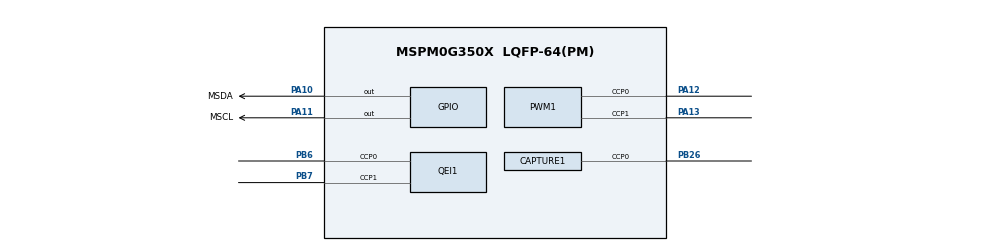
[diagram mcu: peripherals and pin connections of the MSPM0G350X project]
/**
 *
 * @cliArgs --device "MSPM0G350X" --part "Default" --package "LQFP-64(PM)" --product "mspm0_sdk@2.10.00.04"
 * @versions {"tool":"1.28.0+4696"}
 */

/**
 * Import the modules used in this configuration.
 */
const CAPTURE  = scripting.addModule("/ti/driverlib/CAPTURE", {}, false);
const CAPTURE1 = CAPTURE.addInstance();
const GPIO     = scripting.addModule("/ti/driverlib/GPIO", {}, false);
const GPIO1    = GPIO.addInstance();
const GPIO2    = GPIO.addInstance();
const GPIO3    = GPIO.addInstance();
const GPIO4    = GPIO.addInstance();
const GPIO5    = GPIO.addInstance();
const GPIO6    = GPIO.addInstance();
const PWM      = scripting.addModule("/ti/driverlib/PWM", {}, false);
const PWM1     = PWM.addInstance();
const QEI      = scripting.addModule("/ti/driverlib/QEI", {}, false);
const QEI1     = QEI.addInstance();
const SYSCTL   = scripting.addModule("/ti/driverlib/SYSCTL");
const TIMER    = scripting.addModule("/ti/driverlib/TIMER", {}, false);
const TIMER1   = TIMER.addInstance();

/**
 * Write custom configuration values to the imported modules.
 */
CAPTURE1.$name                          = "CAPTURE_0";
CAPTURE1.interrupts                     = ["CC0_UP"];
CAPTURE1.multi_countMode                = "DL_TIMER_COUNT_MODE_UP";
CAPTURE1.captureInputMode               = "multi";
CAPTURE1.multi_countRep                 = "DL_TIMER_REPEAT_MODE_ENABLED";
CAPTURE1.ccIndexMulti                   = [0];
CAPTURE1.peripheral.$assign             = "TIMG6";
CAPTURE1.peripheral.ccp0Pin.$assign     = "PB26";
CAPTURE1.ccp0PinConfig.$name            = "ti_driverlib_gpio_GPIOPinGeneric4";
CAPTURE1.ccp0PinConfig.enableConfig     = true;
CAPTURE1.ccp0PinConfig.internalResistor = "PULL_UP";

const Board = scripting.addModule("/ti/driverlib/Board", {}, false);

GPIO1.$name                              = "GPIO_GRP_0";
GPIO1.port                               = "PORTB";
GPIO1.associatedPins.create(8);
GPIO1.associatedPins[0].$name            = "PIN_9";
GPIO1.associatedPins[0].direction        = "INPUT";
GPIO1.associatedPins[0].assignedPin      = "9";
GPIO1.associatedPins[0].internalResistor = "PULL_UP";
GPIO1.associatedPins[1].$name            = "PIN_10";
GPIO1.associatedPins[1].direction        = "INPUT";
GPIO1.associatedPins[1].internalResistor = "PULL_UP";
GPIO1.associatedPins[1].assignedPin      = "10";
GPIO1.associatedPins[2].$name            = "PIN_11";
GPIO1.associatedPins[2].assignedPin      = "11";
GPIO1.associatedPins[2].direction        = "INPUT";
GPIO1.associatedPins[2].internalResistor = "PULL_UP";
GPIO1.associatedPins[3].$name            = "PIN_12";
GPIO1.associatedPins[3].direction        = "INPUT";
GPIO1.associatedPins[3].internalResistor = "PULL_UP";
GPIO1.associatedPins[3].assignedPin      = "12";
GPIO1.associatedPins[4].$name            = "PIN_13";
GPIO1.associatedPins[4].assignedPin      = "13";
GPIO1.associatedPins[4].direction        = "INPUT";
GPIO1.associatedPins[4].internalResistor = "PULL_UP";
GPIO1.associatedPins[5].$name            = "PIN_14";
GPIO1.associatedPins[5].assignedPin      = "14";
GPIO1.associatedPins[5].direction        = "INPUT";
GPIO1.associatedPins[5].internalResistor = "PULL_UP";
GPIO1.associatedPins[6].$name            = "PIN_15";
GPIO1.associatedPins[6].assignedPin      = "15";
GPIO1.associatedPins[6].direction        = "INPUT";
GPIO1.associatedPins[6].internalResistor = "PULL_UP";
GPIO1.associatedPins[7].$name            = "PIN_16";
GPIO1.associatedPins[7].assignedPin      = "16";
GPIO1.associatedPins[7].direction        = "INPUT";
GPIO1.associatedPins[7].internalResistor = "PULL_UP";

GPIO2.port                               = "PORTB";
GPIO2.$name                              = "OLED";
GPIO2.associatedPins.create(2);
GPIO2.associatedPins[0].internalResistor = "PULL_UP";
GPIO2.associatedPins[0].initialValue     = "SET";
GPIO2.associatedPins[0].assignedPin      = "2";
GPIO2.associatedPins[0].$name            = "OSCL";
GPIO2.associatedPins[1].assignedPin      = "3";
GPIO2.associatedPins[1].initialValue     = "SET";
GPIO2.associatedPins[1].internalResistor = "PULL_UP";
GPIO2.associatedPins[1].$name            = "OSDA";

GPIO3.$name                              = "MPU";
GPIO3.port                               = "PORTA";
GPIO3.associatedPins.create(2);
GPIO3.associatedPins[0].$name            = "MSCL";
GPIO3.associatedPins[0].internalResistor = "PULL_UP";
GPIO3.associatedPins[0].assignedPin      = "11";
GPIO3.associatedPins[0].initialValue     = "SET";
GPIO3.associatedPins[0].hiZ              = "ENABLE";
GPIO3.associatedPins[0].pin.$assign      = "PA11";
GPIO3.associatedPins[1].$name            = "MSDA";
GPIO3.associatedPins[1].internalResistor = "PULL_UP";
GPIO3.associatedPins[1].assignedPin      = "10";
GPIO3.associatedPins[1].initialValue     = "SET";
GPIO3.associatedPins[1].hiZ              = "ENABLE";
GPIO3.associatedPins[1].pin.$assign      = "PA10";

GPIO4.$name                          = "MOTOR";
GPIO4.associatedPins.create(4);
GPIO4.associatedPins[0].$name        = "AIN1";
GPIO4.associatedPins[0].ioStructure  = "SD";
GPIO4.associatedPins[0].assignedPort = "PORTB";
GPIO4.associatedPins[0].assignedPin  = "0";
GPIO4.associatedPins[1].$name        = "AIN2";
GPIO4.associatedPins[1].ioStructure  = "SD";
GPIO4.associatedPins[1].assignedPort = "PORTB";
GPIO4.associatedPins[1].assignedPin  = "1";
GPIO4.associatedPins[2].$name        = "BIN1";
GPIO4.associatedPins[2].ioStructure  = "SD";
GPIO4.associatedPins[2].assignedPort = "PORTA";
GPIO4.associatedPins[2].assignedPin  = "24";
GPIO4.associatedPins[3].$name        = "BIN2";
GPIO4.associatedPins[3].ioStructure  = "SD";
GPIO4.associatedPins[3].assignedPort = "PORTA";
GPIO4.associatedPins[3].assignedPin  = "25";

GPIO5.$name                              = "GPIO_GRP_1";
GPIO5.port                               = "PORTB";
GPIO5.associatedPins[0].$name            = "PIN_0";
GPIO5.associatedPins[0].direction        = "INPUT";
GPIO5.associatedPins[0].ioStructure      = "SD";
GPIO5.associatedPins[0].internalResistor = "PULL_UP";
GPIO5.associatedPins[0].assignedPin      = "27";

GPIO6.$name                              = "KEY";
GPIO6.port                               = "PORTB";
GPIO6.associatedPins[0].initialValue     = "SET";
GPIO6.associatedPins[0].direction        = "INPUT";
GPIO6.associatedPins[0].assignedPin      = "21";
GPIO6.associatedPins[0].internalResistor = "PULL_UP";
GPIO6.associatedPins[0].$name            = "FLAG";

PWM1.$name                              = "PWM_MOTOR";
PWM1.timerCount                         = 100;
PWM1.clockPrescale                      = 16;
PWM1.peripheral.ccp0Pin.$assign         = "PA12";
PWM1.peripheral.ccp1Pin.$assign         = "PA13";
PWM1.PWM_CHANNEL_0.$name                = "ti_driverlib_pwm_PWMTimerCC0";
PWM1.PWM_CHANNEL_1.$name                = "ti_driverlib_pwm_PWMTimerCC1";
PWM1.ccp0PinConfig.direction            = scripting.forceWrite("OUTPUT");
PWM1.ccp0PinConfig.hideOutputInversion  = scripting.forceWrite(false);
PWM1.ccp0PinConfig.onlyInternalResistor = scripting.forceWrite(false);
PWM1.ccp0PinConfig.passedPeripheralType = scripting.forceWrite("Digital");
PWM1.ccp0PinConfig.$name                = "ti_driverlib_gpio_GPIOPinGeneric0";
PWM1.ccp0PinConfig.enableConfig         = true;
PWM1.ccp1PinConfig.direction            = scripting.forceWrite("OUTPUT");
PWM1.ccp1PinConfig.hideOutputInversion  = scripting.forceWrite(false);
PWM1.ccp1PinConfig.onlyInternalResistor = scripting.forceWrite(false);
PWM1.ccp1PinConfig.passedPeripheralType = scripting.forceWrite("Digital");
PWM1.ccp1PinConfig.$name                = "ti_driverlib_gpio_GPIOPinGeneric1";
PWM1.ccp1PinConfig.enableConfig         = true;

QEI1.$name                          = "QEI_0";
QEI1.interrupts                     = ["CC0_UP_EVENT"];
QEI1.peripheral.$assign             = "TIMG8";
QEI1.peripheral.ccp0Pin.$assign     = "PB6";
QEI1.peripheral.ccp1Pin.$assign     = "PB7";
QEI1.ccp0PinConfig.$name            = "ti_driverlib_gpio_GPIOPinGeneric2";
QEI1.ccp0PinConfig.enableConfig     = true;
QEI1.ccp0PinConfig.internalResistor = "PULL_UP";
QEI1.ccp1PinConfig.$name            = "ti_driverlib_gpio_GPIOPinGeneric3";
QEI1.ccp1PinConfig.enableConfig     = true;
QEI1.ccp1PinConfig.internalResistor = "PULL_UP";

SYSCTL.forceDefaultClkConfig = true;

TIMER1.timerMode                        = "PERIODIC";
TIMER1.timerClkDiv                      = 5;
TIMER1.timerPeriod                      = "10 ms";
TIMER1.interrupts                       = ["ZERO"];
TIMER1.$name                            = "TIMER_7";
TIMER1.peripheral.$assignAllowConflicts = "TIMG7";

/**
 * Pinmux solution for unlocked pins/peripherals. This ensures that minor changes to the automatic solver in a future
 * version of the tool will not impact the pinmux you originally saw.  These lines can be completely deleted in order to
 * re-solve from scratch.
 */
Board.peripheral.$suggestSolution            = "DEBUGSS";
Board.peripheral.swclkPin.$suggestSolution   = "PA20";
Board.peripheral.swdioPin.$suggestSolution   = "PA19";
GPIO1.associatedPins[0].pin.$suggestSolution = "PB9";
GPIO1.associatedPins[1].pin.$suggestSolution = "PB10";
GPIO1.associatedPins[2].pin.$suggestSolution = "PB11";
GPIO1.associatedPins[3].pin.$suggestSolution = "PB12";
GPIO1.associatedPins[4].pin.$suggestSolution = "PB13";
GPIO1.associatedPins[5].pin.$suggestSolution = "PB14";
GPIO1.associatedPins[6].pin.$suggestSolution = "PB15";
GPIO1.associatedPins[7].pin.$suggestSolution = "PB16";
GPIO2.associatedPins[0].pin.$suggestSolution = "PB2";
GPIO2.associatedPins[1].pin.$suggestSolution = "PB3";
GPIO4.associatedPins[0].pin.$suggestSolution = "PB0";
GPIO4.associatedPins[1].pin.$suggestSolution = "PB1";
GPIO4.associatedPins[2].pin.$suggestSolution = "PA24";
GPIO4.associatedPins[3].pin.$suggestSolution = "PA25";
GPIO5.associatedPins[0].pin.$suggestSolution = "PB27";
GPIO6.associatedPins[0].pin.$suggestSolution = "PB21";
PWM1.peripheral.$suggestSolution             = "TIMG0";
SYSCTL.peripheral.$suggestSolution           = "SYSCTL";
